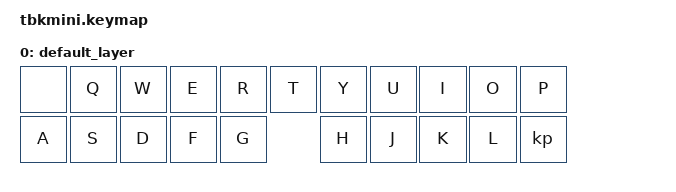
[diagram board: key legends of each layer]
/*
 * Copyright (c) 2021 Casey Webster
 *
 * SPDX-License-Identifier: MIT
 */

#include <behaviors.dtsi>
#include <dt-bindings/zmk/keys.h>

/ {
	keymap {
		compatible = "zmk,keymap";

		default_layer {
// ---------------------------------------------------------------------------------------------------------------------------------
// |  Q  |  W  |  E   |  R   |  T   |    |  Y   |  U   |  I  |  O  |  P  |
// |  A  |  S  |  D   |  F   |  G   |    |  H   |  J   |  K  |  L  |  ;  |
// |  Z  |  X  |  C   |  V   |  B   |    |  N   |  M   |  ,  |  .  |  /  |
//                    | ESC  | SPC  | TAB  |    | RET  | BSPC | DEL |
			bindings = <
	&&kp Q &kp W &kp E &kp R &kp T          &kp Y &kp U  &kp I    &kp O  &kp P
	&kp A &kp S &kp D &kp F &kp G          &kp H &kp J  &kp K     &kp L   &kp ;
	&kp Z &kp X &kp C &kp V &kp B          &kp N &kp M  &kp COMMA &kp DOT &kp FSLH
	                &kp ESC  &kp SPC &kp TAB         &kp RET &kp BSPC &kp DEL
			>;
		};
	};
};
